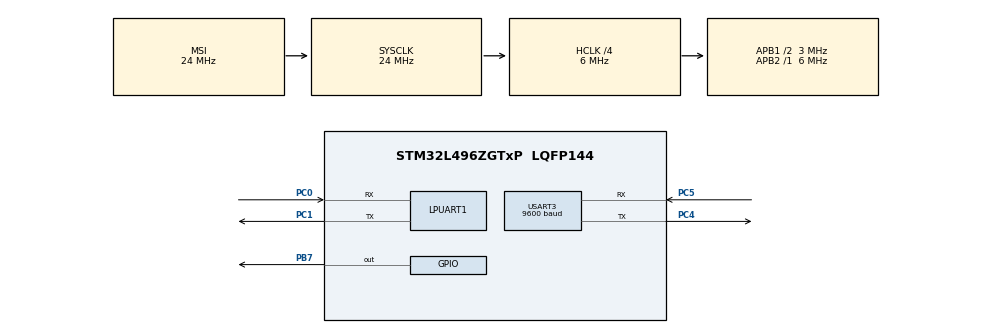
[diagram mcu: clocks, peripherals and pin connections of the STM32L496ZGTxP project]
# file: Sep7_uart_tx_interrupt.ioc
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Dma.Request0=USART3_RX
Dma.USART3_RX.0.Direction=DMA_PERIPH_TO_MEMORY
Dma.USART3_RX.0.Instance=DMA1_Channel3
Dma.USART3_RX.0.MemDataAlignment=DMA_MDATAALIGN_BYTE
Dma.USART3_RX.0.MemInc=DMA_MINC_ENABLE
Dma.USART3_RX.0.Mode=DMA_NORMAL
Dma.USART3_RX.0.PeriphDataAlignment=DMA_PDATAALIGN_BYTE
Dma.USART3_RX.0.PeriphInc=DMA_PINC_DISABLE
Dma.USART3_RX.0.Priority=DMA_PRIORITY_LOW
Mcu.Family=STM32L4
Mcu.Name=STM32L496ZGTxP
Mcu.Package=LQFP144
NVIC.DMA1_Channel3_IRQn=true\:0\:0\:false\:false\:true\:false\:true\:true
NVIC.PriorityGroup=NVIC_PRIORITYGROUP_4
NVIC.USART3_IRQn=true\:0\:0\:false\:false\:true\:true\:true\:true
PA13\ (JTMS/SWDIO).Mode=Serial_Wire
PA13\ (JTMS/SWDIO).Signal=SYS_JTMS-SWDIO
PA14\ (JTCK/SWCLK).Mode=Serial_Wire
PA14\ (JTCK/SWCLK).Signal=SYS_JTCK-SWCLK
PB7.Signal=GPIO_Output
PC0.Mode=Asynchronous
PC0.Signal=LPUART1_RX
PC1.Mode=Asynchronous
PC1.Signal=LPUART1_TX
PC14-OSC32_IN\ (PC14).Mode=LSE-External-Oscillator
PC14-OSC32_IN\ (PC14).Signal=RCC_OSC32_IN
PC15-OSC32_OUT\ (PC15).Mode=LSE-External-Oscillator
PC15-OSC32_OUT\ (PC15).Signal=RCC_OSC32_OUT
PC4.Mode=Asynchronous
PC4.Signal=USART3_TX
PC5.Mode=Asynchronous
PC5.Signal=USART3_RX
PH0-OSC_IN\ (PH0).Mode=HSE-External-Oscillator
PH0-OSC_IN\ (PH0).Signal=RCC_OSC_IN
PH1-OSC_OUT\ (PH1).Mode=HSE-External-Oscillator
PH1-OSC_OUT\ (PH1).Signal=RCC_OSC_OUT
ProjectManager.HeapSize=0x200
ProjectManager.StackSize=0x400
ProjectManager.TargetToolchain=STM32CubeIDE
RCC.48MHZClocksFreq_Value=24000000
RCC.ADCFreq_Value=80000000
RCC.AHBCLKDivider=RCC_SYSCLK_DIV4
RCC.AHBFreq_Value=6000000
RCC.APB1CLKDivider=RCC_HCLK_DIV2
RCC.APB1Freq_Value=3000000
RCC.APB1TimFreq_Value=6000000
RCC.APB2Freq_Value=6000000
RCC.APB2TimFreq_Value=6000000
RCC.CortexFreq_Value=6000000
RCC.HCLKFreq_Value=6000000
RCC.HSE_VALUE=8000000
RCC.HSI48_VALUE=48000000
RCC.HSI_VALUE=16000000
RCC.MSIClockRange=RCC_MSIRANGE_9
RCC.MSI_VALUE=24000000
RCC.PLLMUL=RCC_PLL_MUL9
RCC.PLLN=71
RCC.PLLR=RCC_PLLR_DIV6
RCC.PLLSAI1N=20
RCC.PLLSourceVirtual=RCC_PLLSOURCE_HSE
RCC.PRESCALERUSB=RCC_USBCLKSOURCE_PLL_DIV1_5
RCC.SYSCLKFreq_VALUE=24000000
RCC.SYSCLKSourceVirtual=RCC_SYSCLKSOURCE_PLLCLK
RCC.USBFreq_Value=80000000
RCC.VCOOutputFreq_Value=568000000
USART3.BaudRate=9600
USART3.VirtualMode-Asynchronous=VM_ASYNC
board=NUCLEO-L496ZG-P

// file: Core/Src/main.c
/* USER CODE BEGIN Header */
/**
  ******************************************************************************
  * @file           : main.c
  * @brief          : Main program body
  ******************************************************************************
  * @attention
  *
  * Copyright (c) 2023 STMicroelectronics.
  * All rights reserved.
  *
  * This software is licensed under terms that can be found in the LICENSE file
  * in the root directory of this software component.
  * If no LICENSE file comes with this software, it is provided AS-IS.
  *
  ******************************************************************************
  */
/* USER CODE END Header */
#include "main.h"

UART_HandleTypeDef hlpuart1;
UART_HandleTypeDef huart3;
DMA_HandleTypeDef hdma_usart3_rx;

void SystemClock_Config(void);
static void MX_GPIO_Init(void);
static void MX_DMA_Init(void);
static void MX_LPUART1_UART_Init(void);
static void MX_USART3_UART_Init(void);

/* USER CODE BEGIN 0 */

uint8_t data[2000];

void HAL_UART_TxCpltCallback(UART_HandleTypeDef *huart)
{
   HAL_UART_Transmit_IT(&huart3, data, sizeof (data));
}

/* USER CODE END 0 */

int main(void)
{

  /* MCU Configuration--------------------------------------------------------*/

  /* Reset of all peripherals, Initializes the Flash interface and the Systick. */
  HAL_Init();

  /* Configure the system clock */
  SystemClock_Config();

  /* Initialize all configured peripherals */
  MX_GPIO_Init();
  MX_DMA_Init();
  MX_LPUART1_UART_Init();
  MX_USART3_UART_Init();
  /* USER CODE BEGIN 2 */

  for (int i=0; i<2000; i++)
   {
     data[i] = 'x';
   }

  HAL_UART_Transmit_IT(&huart3, data, sizeof (data));

  /* USER CODE END 2 */

  /* Infinite loop */
  while (1)
  {

    /* USER CODE BEGIN 3 */

	  HAL_GPIO_TogglePin (GPIOB,GPIO_PIN_7);

       HAL_Delay (250);  // 250 ms delay

  }
  /* USER CODE END 3 */
}

void SystemClock_Config(void)
{
  RCC_OscInitTypeDef RCC_OscInitStruct = {0};
  RCC_ClkInitTypeDef RCC_ClkInitStruct = {0};

  /** Configure the main internal regulator output voltage
  */
  if (HAL_PWREx_ControlVoltageScaling(PWR_REGULATOR_VOLTAGE_SCALE1) != HAL_OK)
  {
    Error_Handler();
  }

  /** Initializes the RCC Oscillators according to the specified parameters
  * in the RCC_OscInitTypeDef structure.
  */
  RCC_OscInitStruct.OscillatorType = RCC_OSCILLATORTYPE_MSI;
  RCC_OscInitStruct.MSIState = RCC_MSI_ON;
  RCC_OscInitStruct.MSICalibrationValue = 0;
  RCC_OscInitStruct.MSIClockRange = RCC_MSIRANGE_9;
  RCC_OscInitStruct.PLL.PLLState = RCC_PLL_NONE;
  if (HAL_RCC_OscConfig(&RCC_OscInitStruct) != HAL_OK)
  {
    Error_Handler();
  }

  /** Initializes the CPU, AHB and APB buses clocks
  */
  RCC_ClkInitStruct.ClockType = RCC_CLOCKTYPE_HCLK|RCC_CLOCKTYPE_SYSCLK
                              |RCC_CLOCKTYPE_PCLK1|RCC_CLOCKTYPE_PCLK2;
  RCC_ClkInitStruct.SYSCLKSource = RCC_SYSCLKSOURCE_MSI;
  RCC_ClkInitStruct.AHBCLKDivider = RCC_SYSCLK_DIV4;
  RCC_ClkInitStruct.APB1CLKDivider = RCC_HCLK_DIV2;
  RCC_ClkInitStruct.APB2CLKDivider = RCC_HCLK_DIV1;

  if (HAL_RCC_ClockConfig(&RCC_ClkInitStruct, FLASH_LATENCY_0) != HAL_OK)
  {
    Error_Handler();
  }
}

static void MX_LPUART1_UART_Init(void)
{

  hlpuart1.Instance = LPUART1;
  hlpuart1.Init.BaudRate = 209700;
  hlpuart1.Init.WordLength = UART_WORDLENGTH_7B;
  hlpuart1.Init.StopBits = UART_STOPBITS_1;
  hlpuart1.Init.Parity = UART_PARITY_NONE;
  hlpuart1.Init.Mode = UART_MODE_TX_RX;
  hlpuart1.Init.HwFlowCtl = UART_HWCONTROL_NONE;
  hlpuart1.Init.OneBitSampling = UART_ONE_BIT_SAMPLE_DISABLE;
  hlpuart1.AdvancedInit.AdvFeatureInit = UART_ADVFEATURE_NO_INIT;
  if (HAL_UART_Init(&hlpuart1) != HAL_OK)
  {
    Error_Handler();
  }

}

static void MX_USART3_UART_Init(void)
{

  huart3.Instance = USART3;
  huart3.Init.BaudRate = 9600;
  huart3.Init.WordLength = UART_WORDLENGTH_8B;
  huart3.Init.StopBits = UART_STOPBITS_1;
  huart3.Init.Parity = UART_PARITY_NONE;
  huart3.Init.Mode = UART_MODE_TX_RX;
  huart3.Init.HwFlowCtl = UART_HWCONTROL_NONE;
  huart3.Init.OverSampling = UART_OVERSAMPLING_16;
  huart3.Init.OneBitSampling = UART_ONE_BIT_SAMPLE_DISABLE;
  huart3.AdvancedInit.AdvFeatureInit = UART_ADVFEATURE_NO_INIT;
  if (HAL_UART_Init(&huart3) != HAL_OK)
  {
    Error_Handler();
  }

}

static void MX_DMA_Init(void)
{

  /* DMA controller clock enable */
  __HAL_RCC_DMA1_CLK_ENABLE();

  /* DMA interrupt init */
  /* DMA1_Channel3_IRQn interrupt configuration */
  HAL_NVIC_SetPriority(DMA1_Channel3_IRQn, 0, 0);
  HAL_NVIC_EnableIRQ(DMA1_Channel3_IRQn);

}

static void MX_GPIO_Init(void)
{
  GPIO_InitTypeDef GPIO_InitStruct = {0};

  /* GPIO Ports Clock Enable */
  __HAL_RCC_GPIOC_CLK_ENABLE();
  __HAL_RCC_GPIOH_CLK_ENABLE();
  __HAL_RCC_GPIOA_CLK_ENABLE();
  __HAL_RCC_GPIOB_CLK_ENABLE();

  /*Configure GPIO pin Output Level */
  HAL_GPIO_WritePin(GPIOB, GPIO_PIN_7, GPIO_PIN_RESET);

  /*Configure GPIO pin : PB7 */
  GPIO_InitStruct.Pin = GPIO_PIN_7;
  GPIO_InitStruct.Mode = GPIO_MODE_OUTPUT_PP;
  GPIO_InitStruct.Pull = GPIO_NOPULL;
  GPIO_InitStruct.Speed = GPIO_SPEED_FREQ_LOW;
  HAL_GPIO_Init(GPIOB, &GPIO_InitStruct);

}

void Error_Handler(void)
{
  __disable_irq();
  while (1)
  {
  }
}
